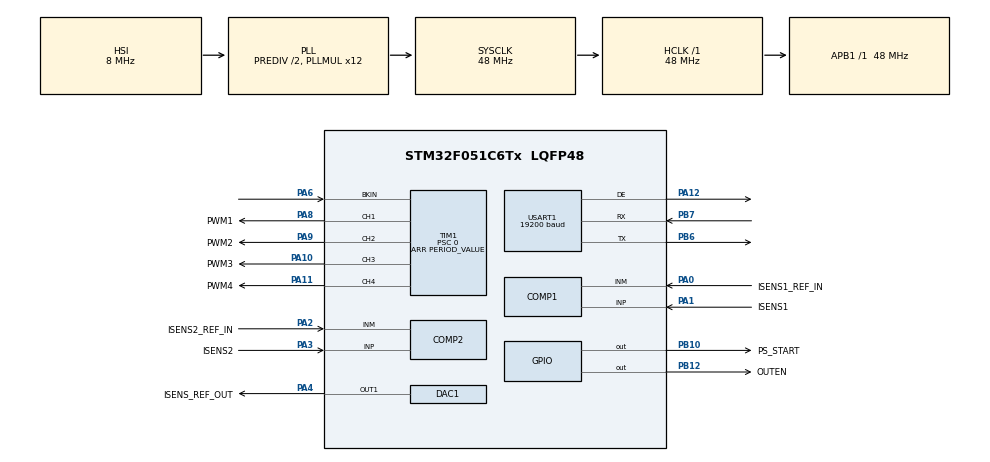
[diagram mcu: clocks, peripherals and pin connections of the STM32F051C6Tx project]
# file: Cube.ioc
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ADC.ClockPrescaler=ADC_CLOCK_ASYNC_DIV1
ADC.ContinuousConvMode=DISABLE
ADC.DMAContinuousRequests=DISABLE
ADC.DataAlign=ADC_DATAALIGN_RIGHT
ADC.DiscontinuousConvMode=DISABLE
ADC.EOCSelection=ADC_EOC_SINGLE_CONV
ADC.EnableAnalogWatchDog=false
ADC.ExternalTrigConv=ADC_SOFTWARE_START
ADC.ExternalTrigConvEdge=ADC_EXTERNALTRIGCONVEDGE_NONE
ADC.LowPowerAutoPowerOff=DISABLE
ADC.LowPowerAutoWait=DISABLE
ADC.Overrun=ADC_OVR_DATA_PRESERVED
ADC.Resolution=ADC_RESOLUTION_12B
ADC.SamplingTime=ADC_SAMPLETIME_1CYCLE_5
ADC.ScanConvMode=ADC_SCAN_DIRECTION_FORWARD
Mcu.Family=STM32F0
Mcu.Name=STM32F051C6Tx
Mcu.Package=LQFP48
Mcu.UserConstants=PERIOD_VALUE,(64 - 1);PULSE1_VALUE,(PERIOD_VALUE/2);PULSE2_VALUE,(PERIOD_VALUE*37.5/100);PULSE3_VALUE,(PERIOD_VALUE/4);PULSE4_VALUE,(PERIOD_VALUE*12.5/100)
NVIC.ADC1_COMP_IRQn=true\:0\:0\:false\:false\:true
NVIC.TIM1_BRK_UP_TRG_COM_IRQn=true\:0\:0\:false\:false\:true
NVIC.TIM6_DAC_IRQn=true\:0\:0\:false\:false\:true
PA0.GPIO_Label=ISENS1_REF_IN
PA0.Mode=INM
PA0.Signal=COMP1_INM
PA1.GPIO_Label=ISENS1
PA1.Mode=INP
PA1.Signal=COMP1_INP
PA10.GPIO_Label=PWM3
PA10.Signal=S_TIM1_CH3
PA11.GPIO_Label=PWM4
PA11.Signal=S_TIM1_CH4
PA12.Mode=Hardware Flow Control (RS485)
PA12.Signal=USART1_DE
PA13.Mode=Serial_Wire
PA13.Signal=SYS_SWDIO
PA14.Mode=Serial_Wire
PA14.Signal=SYS_SWCLK
PA2.GPIO_Label=ISENS2_REF_IN
PA2.Mode=INM
PA2.Signal=COMP2_INM
PA3.GPIO_Label=ISENS2
PA3.Mode=INP
PA3.Signal=COMP2_INP
PA4.GPIO_Label=ISENS_REF_OUT
PA4.Signal=COMP_DAC11_group
PA6.Mode=Activate-Break-Input
PA6.Signal=TIM1_BKIN
PA8.GPIO_Label=PWM1
PA8.Signal=S_TIM1_CH1
PA9.GPIO_Label=PWM2
PA9.Signal=S_TIM1_CH2
PB10.GPIO_Label=PS_START
PB10.Signal=GPIO_Output
PB12.GPIO_Label=OUTEN
PB12.Signal=GPIO_Output
PB6.Mode=Asynchronous
PB6.Signal=USART1_TX
PB7.Mode=Asynchronous
PB7.Signal=USART1_RX
PF0-OSC_IN.Mode=HSE-External-Oscillator
PF0-OSC_IN.Signal=RCC_OSC_IN
PF1-OSC_OUT.Mode=HSE-External-Oscillator
PF1-OSC_OUT.Signal=RCC_OSC_OUT
ProjectManager.HeapSize=0x200
ProjectManager.StackSize=0x400
ProjectManager.TargetToolchain=Other Toolchains (GPDSC)
RCC.AHBFreq_Value=48000000
RCC.APB1Freq_Value=48000000
RCC.APB1TimFreq_Value=48000000
RCC.HCLKFreq_Value=48000000
RCC.HSE_VALUE=32000000
RCC.PLLDivider=RCC_PREDIV_DIV2
RCC.PLLMUL=RCC_PLL_MUL12
RCC.SYSCLKFreq_VALUE=48000000
RCC.SYSCLKSource=RCC_SYSCLKSOURCE_PLLCLK
RCC.Usart1ClockSelection=RCC_USART1CLKSOURCE_SYSCLK
SH.COMP_DAC11_group.0=DAC1_OUT1,DAC_OUT1
SH.S_TIM1_CH1.0=TIM1_CH1,PWM Generation1 CH1
SH.S_TIM1_CH2.0=TIM1_CH2,PWM Generation2 CH2
SH.S_TIM1_CH3.0=TIM1_CH3,PWM Generation3 CH3
SH.S_TIM1_CH4.0=TIM1_CH4,PWM Generation4 CH4
TIM1.AutomaticOutput=TIM_AUTOMATICOUTPUT_ENABLE
TIM1.BreakState=TIM_BREAK_ENABLE
TIM1.Channel-PWM\ Generation1\ CH1=TIM_CHANNEL_1
TIM1.Channel-PWM\ Generation2\ CH2=TIM_CHANNEL_2
TIM1.Channel-PWM\ Generation3\ CH3=TIM_CHANNEL_3
TIM1.Channel-PWM\ Generation4\ CH4=TIM_CHANNEL_4
TIM1.CounterMode=TIM_COUNTERMODE_UP
TIM1.Period=PERIOD_VALUE
TIM1.Prescaler=0
TIM1.Pulse-PWM\ Generation4\ CH4=PULSE4_VALUE
TIM6.Period=1000
TIM6.Prescaler=0
USART1.BaudRate=19200
USART1.VirtualMode-Asynchronous=VM_ASYNC
USART1.VirtualMode-Hardware\ Flow\ Control\ (RS485)=VM_ASYNC
VP_ADC_TempSens_Input.Mode=IN-TempSens
VP_ADC_Vbat_Input.Mode=IN-Vbat
VP_ADC_Vref_Input.Mode=IN-Vrefint
VP_IWDG_VS_IWDG.Mode=IWDG_Activate
VP_TIM1_VS_ClockSourceINT.Mode=Internal
VP_TIM6_VS_ClockSourceINT.Mode=Enable_Timer
board=Cube

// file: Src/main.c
/**
  ******************************************************************************
  * File Name          : main.c
  * Description        : Main program body
  ******************************************************************************
  ** This notice applies to any and all portions of this file
  * that are not between comment pairs USER CODE BEGIN and
  * USER CODE END. Other portions of this file, whether
  * inserted by the user or by software development tools
  * are owned by their respective copyright owners.
  *
  * COPYRIGHT(c) 2017 STMicroelectronics
  *
  * Redistribution and use in source and binary forms, with or without modification,
  * are permitted provided that the following conditions are met:
  *   1. Redistributions of source code must retain the above copyright notice,
  *      this list of conditions and the following disclaimer.
  *   2. Redistributions in binary form must reproduce the above copyright notice,
  *      this list of conditions and the following disclaimer in the documentation
  *      and/or other materials provided with the distribution.
  *   3. Neither the name of STMicroelectronics nor the names of its contributors
  *      may be used to endorse or promote products derived from this software
  *      without specific prior written permission.
  *
  * THIS SOFTWARE IS PROVIDED BY THE COPYRIGHT HOLDERS AND CONTRIBUTORS "AS IS"
  * AND ANY EXPRESS OR IMPLIED WARRANTIES, INCLUDING, BUT NOT LIMITED TO, THE
  * IMPLIED WARRANTIES OF MERCHANTABILITY AND FITNESS FOR A PARTICULAR PURPOSE ARE
  * DISCLAIMED. IN NO EVENT SHALL THE COPYRIGHT HOLDER OR CONTRIBUTORS BE LIABLE
  * FOR ANY DIRECT, INDIRECT, INCIDENTAL, SPECIAL, EXEMPLARY, OR CONSEQUENTIAL
  * DAMAGES (INCLUDING, BUT NOT LIMITED TO, PROCUREMENT OF SUBSTITUTE GOODS OR
  * SERVICES; LOSS OF USE, DATA, OR PROFITS; OR BUSINESS INTERRUPTION) HOWEVER
  * CAUSED AND ON ANY THEORY OF LIABILITY, WHETHER IN CONTRACT, STRICT LIABILITY,
  * OR TORT (INCLUDING NEGLIGENCE OR OTHERWISE) ARISING IN ANY WAY OUT OF THE USE
  * OF THIS SOFTWARE, EVEN IF ADVISED OF THE POSSIBILITY OF SUCH DAMAGE.
  *
  ******************************************************************************
  */
#include "main.h"
#include "stm32f0xx_hal.h"

ADC_HandleTypeDef hadc;

COMP_HandleTypeDef hcomp1;
COMP_HandleTypeDef hcomp2;

DAC_HandleTypeDef hdac1;

IWDG_HandleTypeDef hiwdg;

TIM_HandleTypeDef htim1;
TIM_HandleTypeDef htim6;

UART_HandleTypeDef huart1;

/* USER CODE BEGIN PV */
/* Private variables ---------------------------------------------------------*/
uint8_t var = 0, tmp = 0;
/* USER CODE END PV */

void SystemClock_Config(void);
static void MX_GPIO_Init(void);
static void MX_ADC_Init(void);
static void MX_USART1_UART_Init(void);
static void MX_COMP1_Init(void);
static void MX_COMP2_Init(void);
static void MX_TIM1_Init(void);
static void MX_IWDG_Init(void);
static void MX_TIM6_Init(void);
static void MX_DAC1_Init(void);

void HAL_TIM_MspPostInit(TIM_HandleTypeDef *htim);

/* USER CODE BEGIN PFP */
/* Private function prototypes -----------------------------------------------*/

/* USER CODE END PFP */

int main(void)
{

  /* MCU Configuration----------------------------------------------------------*/

  /* Reset of all peripherals, Initializes the Flash interface and the Systick. */
  HAL_Init();

  /* Configure the system clock */
  SystemClock_Config();

  /* Initialize all configured peripherals */
  MX_GPIO_Init();
  MX_ADC_Init();
  MX_USART1_UART_Init();
  MX_COMP1_Init();
  MX_COMP2_Init();
  MX_TIM1_Init();
  MX_IWDG_Init();
  MX_TIM6_Init();
  MX_DAC1_Init();

  /* USER CODE BEGIN 2 */
    var += 1;
    var &= 0x03;
  /* USER CODE END 2 */

  /* Infinite loop */
  /* USER CODE BEGIN WHILE */
  while (1)
  {
        HAL_GPIO_TogglePin(GPIOB, GPIO_PIN_12);

        var = 0;

        while (var++ < 80){

            tmp = var;

            if( tmp &= 60 ) {
                var = 0;
            }else{

            }

        }

        var = 59;
        var &= 67;

        var = 255;
        var &= 0x03;
  /* USER CODE END WHILE */

  }

}

/** System Clock Configuration
*/
void SystemClock_Config(void)
{

  RCC_OscInitTypeDef RCC_OscInitStruct;
  RCC_ClkInitTypeDef RCC_ClkInitStruct;
  RCC_PeriphCLKInitTypeDef PeriphClkInit;

    /**Initializes the CPU, AHB and APB busses clocks
    */
  RCC_OscInitStruct.OscillatorType = RCC_OSCILLATORTYPE_HSI|RCC_OSCILLATORTYPE_HSI14
                              |RCC_OSCILLATORTYPE_LSI;
  RCC_OscInitStruct.HSIState = RCC_HSI_ON;
  RCC_OscInitStruct.HSI14State = RCC_HSI14_ON;
  RCC_OscInitStruct.HSICalibrationValue = 16;
  RCC_OscInitStruct.HSI14CalibrationValue = 16;
  RCC_OscInitStruct.LSIState = RCC_LSI_ON;
  RCC_OscInitStruct.PLL.PLLState = RCC_PLL_ON;
  RCC_OscInitStruct.PLL.PLLSource = RCC_PLLSOURCE_HSI;
  RCC_OscInitStruct.PLL.PLLMUL = RCC_PLL_MUL12;
  RCC_OscInitStruct.PLL.PREDIV = RCC_PREDIV_DIV2;
  if (HAL_RCC_OscConfig(&RCC_OscInitStruct) != HAL_OK)
  {
    _Error_Handler(__FILE__, __LINE__);
  }

    /**Initializes the CPU, AHB and APB busses clocks
    */
  RCC_ClkInitStruct.ClockType = RCC_CLOCKTYPE_HCLK|RCC_CLOCKTYPE_SYSCLK
                              |RCC_CLOCKTYPE_PCLK1;
  RCC_ClkInitStruct.SYSCLKSource = RCC_SYSCLKSOURCE_PLLCLK;
  RCC_ClkInitStruct.AHBCLKDivider = RCC_SYSCLK_DIV1;
  RCC_ClkInitStruct.APB1CLKDivider = RCC_HCLK_DIV1;

  if (HAL_RCC_ClockConfig(&RCC_ClkInitStruct, FLASH_LATENCY_1) != HAL_OK)
  {
    _Error_Handler(__FILE__, __LINE__);
  }

  PeriphClkInit.PeriphClockSelection = RCC_PERIPHCLK_USART1;
  PeriphClkInit.Usart1ClockSelection = RCC_USART1CLKSOURCE_SYSCLK;
  if (HAL_RCCEx_PeriphCLKConfig(&PeriphClkInit) != HAL_OK)
  {
    _Error_Handler(__FILE__, __LINE__);
  }

    /**Configure the Systick interrupt time
    */
  HAL_SYSTICK_Config(HAL_RCC_GetHCLKFreq()/1000);

    /**Configure the Systick
    */
  HAL_SYSTICK_CLKSourceConfig(SYSTICK_CLKSOURCE_HCLK);

  /* SysTick_IRQn interrupt configuration */
  HAL_NVIC_SetPriority(SysTick_IRQn, 0, 0);
}

/* ADC init function */
static void MX_ADC_Init(void)
{

  ADC_ChannelConfTypeDef sConfig;

    /**Configure the global features of the ADC (Clock, Resolution, Data Alignment and number of conversion)
    */
  hadc.Instance = ADC1;
  hadc.Init.ClockPrescaler = ADC_CLOCK_ASYNC_DIV1;
  hadc.Init.Resolution = ADC_RESOLUTION_12B;
  hadc.Init.DataAlign = ADC_DATAALIGN_RIGHT;
  hadc.Init.ScanConvMode = ADC_SCAN_DIRECTION_FORWARD;
  hadc.Init.EOCSelection = ADC_EOC_SINGLE_CONV;
  hadc.Init.LowPowerAutoWait = DISABLE;
  hadc.Init.LowPowerAutoPowerOff = DISABLE;
  hadc.Init.ContinuousConvMode = DISABLE;
  hadc.Init.DiscontinuousConvMode = DISABLE;
  hadc.Init.ExternalTrigConv = ADC_SOFTWARE_START;
  hadc.Init.ExternalTrigConvEdge = ADC_EXTERNALTRIGCONVEDGE_NONE;
  hadc.Init.DMAContinuousRequests = DISABLE;
  hadc.Init.Overrun = ADC_OVR_DATA_PRESERVED;
  if (HAL_ADC_Init(&hadc) != HAL_OK)
  {
    _Error_Handler(__FILE__, __LINE__);
  }

    /**Configure for the selected ADC regular channel to be converted.
    */
  sConfig.Channel = ADC_CHANNEL_TEMPSENSOR;
  sConfig.Rank = ADC_RANK_CHANNEL_NUMBER;
  sConfig.SamplingTime = ADC_SAMPLETIME_1CYCLE_5;
  if (HAL_ADC_ConfigChannel(&hadc, &sConfig) != HAL_OK)
  {
    _Error_Handler(__FILE__, __LINE__);
  }

    /**Configure for the selected ADC regular channel to be converted.
    */
  sConfig.Channel = ADC_CHANNEL_VREFINT;
  if (HAL_ADC_ConfigChannel(&hadc, &sConfig) != HAL_OK)
  {
    _Error_Handler(__FILE__, __LINE__);
  }

    /**Configure for the selected ADC regular channel to be converted.
    */
  sConfig.Channel = ADC_CHANNEL_VBAT;
  if (HAL_ADC_ConfigChannel(&hadc, &sConfig) != HAL_OK)
  {
    _Error_Handler(__FILE__, __LINE__);
  }

}

/* COMP1 init function */
static void MX_COMP1_Init(void)
{

  hcomp1.Instance = COMP1;
  hcomp1.Init.InvertingInput = COMP_INVERTINGINPUT_IO1;
  hcomp1.Init.NonInvertingInput = COMP_NONINVERTINGINPUT_IO1;
  hcomp1.Init.Output = COMP_OUTPUT_NONE;
  hcomp1.Init.OutputPol = COMP_OUTPUTPOL_NONINVERTED;
  hcomp1.Init.Hysteresis = COMP_HYSTERESIS_NONE;
  hcomp1.Init.Mode = COMP_MODE_HIGHSPEED;
  hcomp1.Init.WindowMode = COMP_WINDOWMODE_DISABLE;
  hcomp1.Init.TriggerMode = COMP_TRIGGERMODE_NONE;
  if (HAL_COMP_Init(&hcomp1) != HAL_OK)
  {
    _Error_Handler(__FILE__, __LINE__);
  }

}

/* COMP2 init function */
static void MX_COMP2_Init(void)
{

  hcomp2.Instance = COMP2;
  hcomp2.Init.InvertingInput = COMP_INVERTINGINPUT_IO1;
  hcomp2.Init.NonInvertingInput = COMP_NONINVERTINGINPUT_IO1;
  hcomp2.Init.Output = COMP_OUTPUT_NONE;
  hcomp2.Init.OutputPol = COMP_OUTPUTPOL_NONINVERTED;
  hcomp2.Init.Hysteresis = COMP_HYSTERESIS_NONE;
  hcomp2.Init.Mode = COMP_MODE_HIGHSPEED;
  hcomp2.Init.WindowMode = COMP_WINDOWMODE_DISABLE;
  hcomp2.Init.TriggerMode = COMP_TRIGGERMODE_NONE;
  if (HAL_COMP_Init(&hcomp2) != HAL_OK)
  {
    _Error_Handler(__FILE__, __LINE__);
  }

}

/* DAC1 init function */
static void MX_DAC1_Init(void)
{

  DAC_ChannelConfTypeDef sConfig;

    /**DAC Initialization
    */
  hdac1.Instance = DAC;
  if (HAL_DAC_Init(&hdac1) != HAL_OK)
  {
    _Error_Handler(__FILE__, __LINE__);
  }

    /**DAC channel OUT1 config
    */
  sConfig.DAC_Trigger = DAC_TRIGGER_NONE;
  sConfig.DAC_OutputBuffer = DAC_OUTPUTBUFFER_ENABLE;
  if (HAL_DAC_ConfigChannel(&hdac1, &sConfig, DAC_CHANNEL_1) != HAL_OK)
  {
    _Error_Handler(__FILE__, __LINE__);
  }

}

/* IWDG init function */
static void MX_IWDG_Init(void)
{

  hiwdg.Instance = IWDG;
  hiwdg.Init.Prescaler = IWDG_PRESCALER_4;
  hiwdg.Init.Window = 4095;
  hiwdg.Init.Reload = 4095;
  if (HAL_IWDG_Init(&hiwdg) != HAL_OK)
  {
    _Error_Handler(__FILE__, __LINE__);
  }

}

/* TIM1 init function */
static void MX_TIM1_Init(void)
{

  TIM_ClockConfigTypeDef sClockSourceConfig;
  TIM_MasterConfigTypeDef sMasterConfig;
  TIM_OC_InitTypeDef sConfigOC;
  TIM_BreakDeadTimeConfigTypeDef sBreakDeadTimeConfig;

  htim1.Instance = TIM1;
  htim1.Init.Prescaler = 0;
  htim1.Init.CounterMode = TIM_COUNTERMODE_UP;
  htim1.Init.Period = PERIOD_VALUE;
  htim1.Init.ClockDivision = TIM_CLOCKDIVISION_DIV1;
  htim1.Init.RepetitionCounter = 0;
  htim1.Init.AutoReloadPreload = TIM_AUTORELOAD_PRELOAD_DISABLE;
  if (HAL_TIM_Base_Init(&htim1) != HAL_OK)
  {
    _Error_Handler(__FILE__, __LINE__);
  }

  sClockSourceConfig.ClockSource = TIM_CLOCKSOURCE_INTERNAL;
  if (HAL_TIM_ConfigClockSource(&htim1, &sClockSourceConfig) != HAL_OK)
  {
    _Error_Handler(__FILE__, __LINE__);
  }

  if (HAL_TIM_PWM_Init(&htim1) != HAL_OK)
  {
    _Error_Handler(__FILE__, __LINE__);
  }

  sMasterConfig.MasterOutputTrigger = TIM_TRGO_RESET;
  sMasterConfig.MasterSlaveMode = TIM_MASTERSLAVEMODE_DISABLE;
  if (HAL_TIMEx_MasterConfigSynchronization(&htim1, &sMasterConfig) != HAL_OK)
  {
    _Error_Handler(__FILE__, __LINE__);
  }

  sConfigOC.OCMode = TIM_OCMODE_PWM1;
  sConfigOC.Pulse = 0;
  sConfigOC.OCPolarity = TIM_OCPOLARITY_HIGH;
  sConfigOC.OCNPolarity = TIM_OCNPOLARITY_HIGH;
  sConfigOC.OCFastMode = TIM_OCFAST_DISABLE;
  sConfigOC.OCIdleState = TIM_OCIDLESTATE_RESET;
  sConfigOC.OCNIdleState = TIM_OCNIDLESTATE_RESET;
  if (HAL_TIM_PWM_ConfigChannel(&htim1, &sConfigOC, TIM_CHANNEL_1) != HAL_OK)
  {
    _Error_Handler(__FILE__, __LINE__);
  }

  if (HAL_TIM_PWM_ConfigChannel(&htim1, &sConfigOC, TIM_CHANNEL_2) != HAL_OK)
  {
    _Error_Handler(__FILE__, __LINE__);
  }

  if (HAL_TIM_PWM_ConfigChannel(&htim1, &sConfigOC, TIM_CHANNEL_3) != HAL_OK)
  {
    _Error_Handler(__FILE__, __LINE__);
  }

  sConfigOC.Pulse = PULSE4_VALUE;
  if (HAL_TIM_PWM_ConfigChannel(&htim1, &sConfigOC, TIM_CHANNEL_4) != HAL_OK)
  {
    _Error_Handler(__FILE__, __LINE__);
  }

  sBreakDeadTimeConfig.OffStateRunMode = TIM_OSSR_DISABLE;
  sBreakDeadTimeConfig.OffStateIDLEMode = TIM_OSSI_DISABLE;
  sBreakDeadTimeConfig.LockLevel = TIM_LOCKLEVEL_OFF;
  sBreakDeadTimeConfig.DeadTime = 0;
  sBreakDeadTimeConfig.BreakState = TIM_BREAK_ENABLE;
  sBreakDeadTimeConfig.BreakPolarity = TIM_BREAKPOLARITY_HIGH;
  sBreakDeadTimeConfig.AutomaticOutput = TIM_AUTOMATICOUTPUT_ENABLE;
  if (HAL_TIMEx_ConfigBreakDeadTime(&htim1, &sBreakDeadTimeConfig) != HAL_OK)
  {
    _Error_Handler(__FILE__, __LINE__);
  }

  HAL_TIM_MspPostInit(&htim1);

}

/* TIM6 init function */
static void MX_TIM6_Init(void)
{

  TIM_MasterConfigTypeDef sMasterConfig;

  htim6.Instance = TIM6;
  htim6.Init.Prescaler = 0;
  htim6.Init.CounterMode = TIM_COUNTERMODE_UP;
  htim6.Init.Period = 1000;
  htim6.Init.AutoReloadPreload = TIM_AUTORELOAD_PRELOAD_DISABLE;
  if (HAL_TIM_Base_Init(&htim6) != HAL_OK)
  {
    _Error_Handler(__FILE__, __LINE__);
  }

  sMasterConfig.MasterOutputTrigger = TIM_TRGO_RESET;
  sMasterConfig.MasterSlaveMode = TIM_MASTERSLAVEMODE_DISABLE;
  if (HAL_TIMEx_MasterConfigSynchronization(&htim6, &sMasterConfig) != HAL_OK)
  {
    _Error_Handler(__FILE__, __LINE__);
  }

}

/* USART1 init function */
static void MX_USART1_UART_Init(void)
{

  huart1.Instance = USART1;
  huart1.Init.BaudRate = 19200;
  huart1.Init.WordLength = UART_WORDLENGTH_8B;
  huart1.Init.StopBits = UART_STOPBITS_1;
  huart1.Init.Parity = UART_PARITY_NONE;
  huart1.Init.Mode = UART_MODE_TX_RX;
  huart1.Init.HwFlowCtl = UART_HWCONTROL_NONE;
  huart1.Init.OverSampling = UART_OVERSAMPLING_16;
  huart1.Init.OneBitSampling = UART_ONE_BIT_SAMPLE_DISABLE;
  huart1.AdvancedInit.AdvFeatureInit = UART_ADVFEATURE_NO_INIT;
  if (HAL_RS485Ex_Init(&huart1, UART_DE_POLARITY_HIGH, 0, 0) != HAL_OK)
  {
    _Error_Handler(__FILE__, __LINE__);
  }

}

/** Configure pins as
        * Analog
        * Input
        * Output
        * EVENT_OUT
        * EXTI
*/
static void MX_GPIO_Init(void)
{

  GPIO_InitTypeDef GPIO_InitStruct;

  /* GPIO Ports Clock Enable */
  __HAL_RCC_GPIOF_CLK_ENABLE();
  __HAL_RCC_GPIOA_CLK_ENABLE();
  __HAL_RCC_GPIOB_CLK_ENABLE();

  /*Configure GPIO pin Output Level */
  HAL_GPIO_WritePin(GPIOB, PS_START_Pin|OUTEN_Pin, GPIO_PIN_RESET);

  /*Configure GPIO pins : PS_START_Pin OUTEN_Pin */
  GPIO_InitStruct.Pin = PS_START_Pin|OUTEN_Pin;
  GPIO_InitStruct.Mode = GPIO_MODE_OUTPUT_PP;
  GPIO_InitStruct.Pull = GPIO_NOPULL;
  GPIO_InitStruct.Speed = GPIO_SPEED_FREQ_LOW;
  HAL_GPIO_Init(GPIOB, &GPIO_InitStruct);

}

void _Error_Handler(char * file, int line)
{
  while(1)
  {
  }
}

/************************ (C) COPYRIGHT STMicroelectronics *****END OF FILE****/
